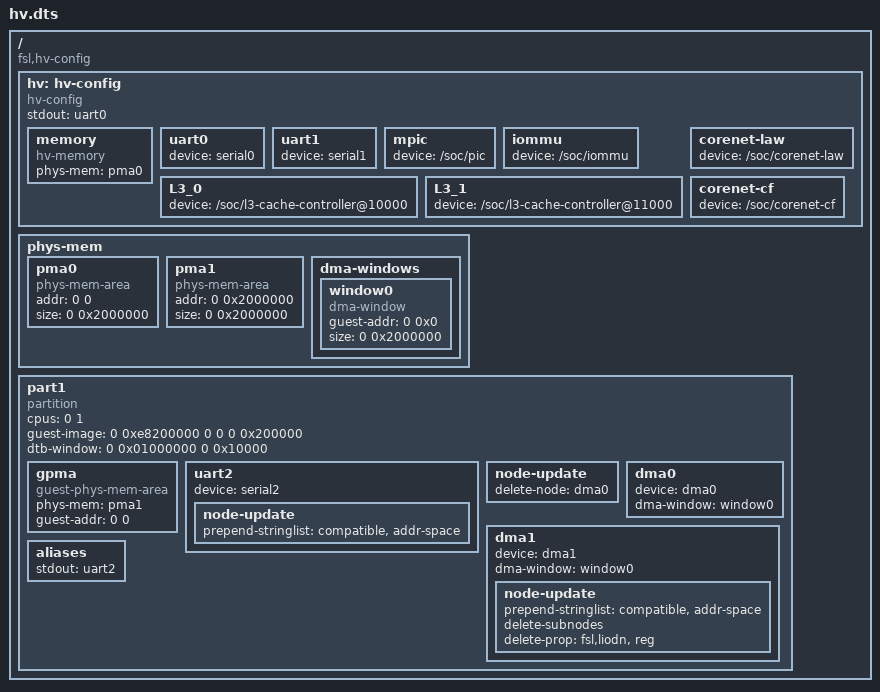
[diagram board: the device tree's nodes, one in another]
/*
 * Copyright (C) 2008,2009 Freescale Semiconductor, Inc.
 *
 * Redistribution and use in source and binary forms, with or without
 * modification, are permitted provided that the following conditions
 * are met:
 * 1. Redistributions of source code must retain the above copyright
 *    notice, this list of conditions and the following disclaimer.
 * 2. Redistributions in binary form must reproduce the above copyright
 *    notice, this list of conditions and the following disclaimer in the
 *    documentation and/or other materials provided with the distribution.
 *
 * THIS SOFTWARE IS PROVIDED BY THE AUTHOR "AS IS" AND ANY EXPRESS OR
 * IMPLIED WARRANTIES, INCLUDING, BUT NOT LIMITED TO, THE IMPLIED WARRANTIES
 * OF MERCHANTABILITY AND FITNESS FOR A PARTICULAR PURPOSE ARE DISCLAIMED.  IN
 * NO EVENT SHALL THE AUTHOR BE LIABLE FOR ANY DIRECT, INDIRECT, INCIDENTAL,
 * SPECIAL, EXEMPLARY, OR CONSEQUENTIAL DAMAGES (INCLUDING, BUT NOT LIMITED
 * TO, PROCUREMENT OF SUBSTITUTE GOODS OR SERVICES; LOSS OF USE, DATA, OR
 * PROFITS; OR BUSINESS INTERRUPTION) HOWEVER CAUSED AND ON ANY THEORY OF
 * LIABILITY, WHETHER IN CONTRACT, STRICT LIABILITY, OR TORT (INCLUDING
 * NEGLIGENCE OR OTHERWISE) ARISING IN ANY WAY OUT OF THE USE OF THIS
 * SOFTWARE, EVEN IF ADVISED OF THE POSSIBILITY OF SUCH DAMAGE.
 */

/dts-v1/;

/ {
	compatible = "fsl,hv-config";

	// =====================================================
	// Hypervisor Config
	// =====================================================
	hv: hv-config {
		compatible = "hv-config";
		stdout = <&uart0>;

		memory {
			compatible = "hv-memory";
			phys-mem = <&pma0>;
		};

		uart0: uart0 {
			device = "serial0";
		};

		uart1: uart1 {
			device = "serial1";
		};

		mpic {
			device = "/soc/pic";
		};

		iommu {
			device = "/soc/iommu";
		};

		L3_0:L3_0 {
			device ="/soc/l3-cache-controller@10000";
		};

		L3_1:L3_1 {
			device ="/soc/l3-cache-controller@11000";
		};

		corenet-law {
			device = "/soc/corenet-law";
		};

		corenet-cf {
			device = "/soc/corenet-cf";
		};

	};

	// =====================================================
	// Physical Memory Areas
	// =====================================================
	phys-mem {
		pma0: pma0 {
			compatible = "phys-mem-area";
			addr = <0 0>;
			size = <0 0x2000000>;
		};

		pma1: pma1 {
			compatible = "phys-mem-area";
			addr = <0 0x2000000>;
			size = <0 0x2000000>;
		};


		dma-windows {
			window0: window0 {
				compatible = "dma-window";
				guest-addr = <0 0x0>;
				size = <0 0x2000000>;
			};
		};

	};

	// =====================================================
	// Partition 1
	// =====================================================
	part1 {
		compatible = "partition";
		cpus = <0 1>;
		guest-image = <0 0xe8200000 0 0 0 0x200000>;
		dtb-window = <0 0x01000000 0 0x10000>;

		gpma {
			compatible = "guest-phys-mem-area";
			phys-mem = <&pma1>;
			guest-addr = <0 0>;
		};

		uart2: uart2 {
			device = "serial2";
			node-update {
				prepend-stringlist = "compatible", "addr-space";
			};
		};

		node-update {
			delete-node = "dma0";
		};

		dma0: dma0 {
			device = "dma0";
			dma-window = <&window0>;
		};

		dma1: dma1 {
			device = "dma1";
			dma-window = <&window0>;
			node-update {
				prepend-stringlist = "compatible", "addr-space";
				delete-subnodes;
				delete-prop = "fsl,liodn", "reg";
			};
		};

		aliases {
			stdout = <&uart2>;
		};
	};

};
